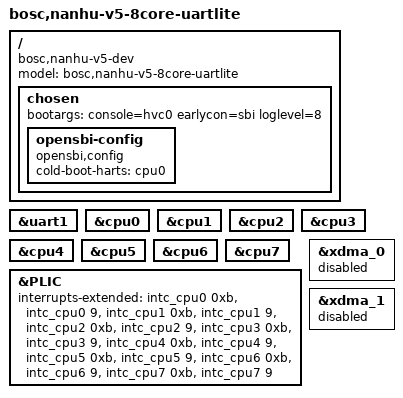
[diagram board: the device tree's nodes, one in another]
// SPDX-License-Identifier: (GPL-2.0 OR MIT)
/* Copyright (c) 2025 BOSC */

/dts-v1/;
#include "nanhu-v5.dtsi"

/ {
	#address-cells = <2>;
	#size-cells = <2>;
	compatible = "bosc,nanhu-v5-dev";
	model = "bosc,nanhu-v5-8core-uartlite";

	chosen {
		bootargs = "console=hvc0 earlycon=sbi loglevel=8";
		opensbi-config {
		    compatible = "opensbi,config";
		    cold-boot-harts = <&cpu0>;
		};
	};
};

&uart1 {
	status = "okay";
};

&cpu0 {
	status = "okay";
};

&cpu1 {
	status = "okay";
};

&cpu2 {
	status = "okay";
};

&cpu3 {
	status = "okay";
};

&cpu4 {
	status = "okay";
};

&cpu5 {
	status = "okay";
};

&cpu6 {
	status = "okay";
};

&cpu7 {
	status = "okay";
};
&PLIC {

	interrupts-extended =
		<&intc_cpu0  0xb>, <&intc_cpu0	9>,
		<&intc_cpu1  0xb>, <&intc_cpu1 	9>,
		<&intc_cpu2  0xb>, <&intc_cpu2 	9>,
		<&intc_cpu3  0xb>, <&intc_cpu3 	9>,
		<&intc_cpu4  0xb>, <&intc_cpu4 	9>,
		<&intc_cpu5  0xb>, <&intc_cpu5 	9>,
		<&intc_cpu6  0xb>, <&intc_cpu6 	9>,
		<&intc_cpu7  0xb>, <&intc_cpu7 	9>;
};
&xdma_0 {
	status = "disabled";
};
&xdma_1 {
	status = "disabled";
};
